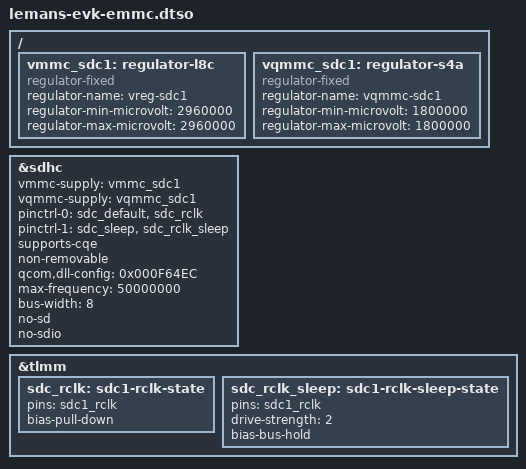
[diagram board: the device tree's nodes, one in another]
// SPDX-License-Identifier: BSD-3-Clause
/*
 * Copyright (c) Qualcomm Technologies, Inc. and/or its subsidiaries.
 */

/dts-v1/;
/plugin/;

#include <dt-bindings/gpio/gpio.h>
#include <dt-bindings/clock/qcom,rpmh.h>
#include <dt-bindings/clock/qcom,sa8775p-gcc.h>

/ {
	vmmc_sdc1: regulator-l8c {
		compatible = "regulator-fixed";
		regulator-name = "vreg-sdc1";

		regulator-min-microvolt = <2960000>;
		regulator-max-microvolt = <2960000>;
	};

	vqmmc_sdc1: regulator-s4a {
		compatible = "regulator-fixed";
		regulator-name = "vqmmc-sdc1";

		regulator-min-microvolt = <1800000>;
		regulator-max-microvolt = <1800000>;
	};
};

&sdhc {
	vmmc-supply = <&vmmc_sdc1>;
	vqmmc-supply = <&vqmmc_sdc1>;

	pinctrl-0 = <&sdc_default>, <&sdc_rclk>;
	pinctrl-1 = <&sdc_sleep>, <&sdc_rclk_sleep>;

	pinctrl-names = "default", "sleep";

	supports-cqe;
	non-removable;

	qcom,dll-config = <0x000F64EC>;
	max-frequency = <50000000>;

	bus-width = <8>;
	no-sd;
	no-sdio;

	status = "okay";
};

&tlmm {
        sdc_rclk: sdc1-rclk-state {
                pins = "sdc1_rclk";
                bias-pull-down;
        };

        sdc_rclk_sleep: sdc1-rclk-sleep-state {
                pins = "sdc1_rclk";
                drive-strength = <2>;
                bias-bus-hold;
        };
};
